# ADS1015 register map
Vendor: Google Inc.; File version: 0.1.0
Texas Instruments Analog-Digital Converter
Registers are 16-bit, read-write, reset 0x0 unless marked. A register's access mark holds for its fields unless they carry their own. Offsets are from the block's base; lines under a group give offsets from that group; [hi:lo] are bit positions; {n}, {i} and the like mark numbered series; 'fields as' and 'values as' point back to an identical list; <NAME> marks a mode.

## Memory map
0x00000049 ADS1015 size 0xFF — Texas Instruments Analog-Digital Converter

## ADS1015 — Texas Instruments Analog-Digital Converter
Base 0x00000049
0x00 Conversion read (reset mask 0xFF) — Conversion register contains the result of the last conversion
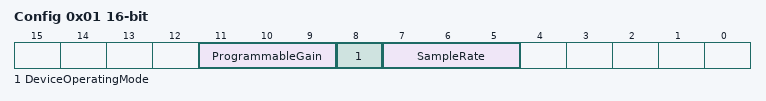
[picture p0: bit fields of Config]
0x01 Config (reset mask 0xFF) — Describes the specifics of the sensing implementation
  [11:9] ProgrammableGain wo range 9..11 — This sets the programmable gain for reading analog voltage
    5=PGA0_256 (Plus/minus 0.256V); 4=PGA0_512 (Plus/minus 0.512V); 3=PGA1_024V (Plus/minus 1.024V); 2=PGA2_048V (Plus/minus 2.048V); 1=PGA4_096V (Plus/minus 4.096V); 0=PGA6_144V (Plus/minus 6.144V)
  [8] DeviceOperatingMode wo range 8..8 — This bit controls the operating mode
    0=CONTINUOUS_CONVERSION; 1=SINGLE_SHOT (Single-shot or power-down state)
  [7:5] SampleRate wo range 5..7 — This sets the samples-per-second value
    0=HZ128 (128 samples/second); 4=HZ1600 (1600 samples/second); 5=HZ2400 (2400 samples/second); 1=HZ250 (250 samples/second); 6=HZ3300 (3300 samples/second); 2=HZ490 (490 samples/second); 3=HZ920 (920 samples/second)

## Licence text in the file
Copyright (C) 2019 Google Inc. Licensed under the Apache License, Version 2.0 (the "License"); you may not use this file except in compliance with the License. You may obtain a copy of the License at http://www.apache.org/licenses/LICENSE-2.0 Unless required by applicable law or agreed to in writing, software distributed under the License is distributed on an "AS IS" BASIS, WITHOUT WARRANTIES OR CONDITIONS OF ANY KIND, either express or implied. See the License for the specific language governing permissions and limitations under the License.
